# SA3_SS_PKTDMA_0_PKTDMA_RXFCFG_44911000h register map
Vendor: Texas Instruments
Peripheral module from a debugger description file (folder AM275x).
Registers are 32-bit, read-write, reset 0x0 unless marked. A register's access mark holds for its fields unless they carry their own. Offsets are as the file gives them; lines under a group give offsets from that group; [hi:lo] are bit positions; {n}, {i} and the like mark numbered series; 'fields as' and 'values as' point back to an identical list; <NAME> marks a mode.

## pktdma_rxfcfg
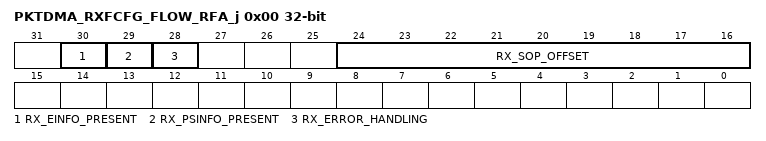
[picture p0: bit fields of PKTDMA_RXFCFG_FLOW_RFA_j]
0x00 PKTDMA_RXFCFG_FLOW_RFA_j — The Rx Flow N Configuration Register A contains static configuration information for the Rx DMA flow. The fields in this register can only be changed when all of the DMA channels that use this flow have been disabled. The fields in this register are as follows:
  [30] RX_EINFO_PRESENT — Rx Extended Packet Info Block Present: This bit controls whether or not the Extended Packet Info Block will be present in the Rx Packet Descriptor. If this bit is clear, the port DMA will clear the Extended Packet Info Present bit in the PD and will drop any Timestamp or SW Data words that are presented from the back end application. If this bit is set, the port DMA will set the Extended Packet Info Block Present bit in the PD and will copy any Timestamp or SW Data words that are presented across the Rx streaming interface into the Extended Packet Info Block words in the descriptor. If no Timestamp or SW Data words are presented from the back end application, the port DMA will overwrite the fields in the PD with zeroes. Reset Source: rst_mod_g_rst_n
  [29] RX_PSINFO_PRESENT — Rx PS Words Present: This bit controls whether or not the Protocol Specific words will be present in the Rx Packet Descriptor. If this bit is clear, the port DMA will set the PS word count to 0 in the PD and will drop any PS words that are presented from the back end application. If this bit is set, the port DMA will set the PS word count to the value given by the back end application and will copy the PS words from the back end application to the location Reset Source: rst_mod_g_rst_n
  [28] RX_ERROR_HANDLING — Rx Error Handling Mode: This bit controls the error handling mode for the flow and is only used when channel errors (i.e. descriptor starvation) occurs. 0 = Starvation errors result in dropping packet and incrementing dropped packet count. 1 = Starvation errors result in the channel waiting until descriptors are added to the free queue before the channel will be scheduled. Reset Source: rst_mod_g_rst_n
  [24:16] RX_SOP_OFFSET — Rx Start of Packet Offset: This field specifies the number of bytes that are to be skipped in the SOP buffer before beginning to write the payload or protocol specific bytes(if they are in the sop buffer). This value must be less than the minimum size of a buffer in the system. Valid values are 0 - 255 bytes. The primary purpose of this field is to ensure that space is left in the descriptor to place the protocol specific information without overwriting or being overwritten by the Rx data. The secondary purpose of this field is to allow space to be left prior to the data in the descriptor in case header information needs to be added as the packet is passed thorough the system. Reset Source: rst_mod_g_rst_n
